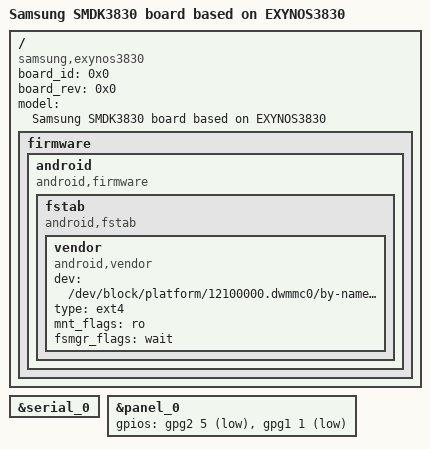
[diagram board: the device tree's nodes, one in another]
/*
 * SAMSUNG EXYNOS3830 board device tree source
 *
 * Copyright (c) 2018 Samsung Electronics Co., Ltd.
 *		http://www.samsung.com
 *
 * This program is free software; you can redistribute it and/or modify
 * it under the terms of the GNU General Public License version 2 as
 * published by the Free Software Foundation.
*/

/dts-v1/;
/plugin/;
#include "exynos3830-board_common.dtsi"

/ {
	compatible = "samsung,exynos3830", "samsung,SMDK3830";
	board_id = <0x0>;
	board_rev = <0x0>;

	fragment@model {
		target-path = "/";
		__overlay__ {
			#address-cells = <2>;
			#size-cells = <1>;

			model = "Samsung SMDK3830 board based on EXYNOS3830";

			firmware {
				android {
					compatible = "android,firmware";
					fstab {
						compatible = "android,fstab";
						vendor {
							compatible = "android,vendor";
							dev = "/dev/block/platform/12100000.dwmmc0/by-name/vendor";
							type = "ext4";
							mnt_flags = "ro";
							fsmgr_flags = "wait";
						};
					};
				};
			};
		}; /* end of __overlay__ */
	}; /* end of fragment */
}; /* end of root */

&serial_0 {
	status = "okay";
};

&panel_0 {
    /* reset, power */
    gpios = <&gpg2 5 0x1>, <&gpg1 1 0x1>;
};
